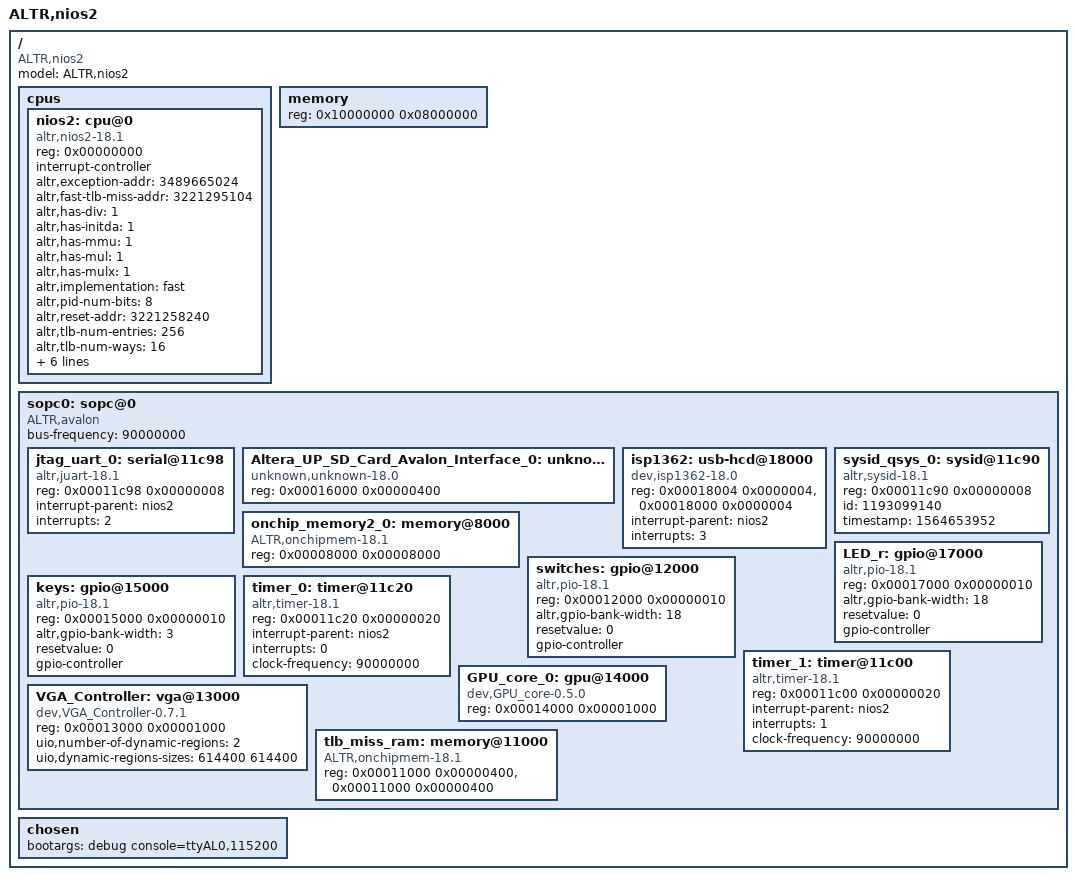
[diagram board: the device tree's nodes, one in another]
/*
 * This devicetree is generated by sopc2dts version unknown on Thu Aug 01 06:11:34 EDT 2019
 * Sopc2dts is written by Walter Goossens <waltergoossens@home.nl>
 * in cooperation with the nios2 community <nios2-dev@lists.rocketboards.org>
 */
/dts-v1/;

/ {
	model = "ALTR,nios2";
	compatible = "ALTR,nios2";
	#address-cells = <1>;
	#size-cells = <1>;

	cpus {
		#address-cells = <1>;
		#size-cells = <0>;

		nios2: cpu@0 {
			device_type = "cpu";
			compatible = "altr,nios2-18.1", "altr,nios2-1.1";
			reg = <0x00000000>;
			interrupt-controller;
			#interrupt-cells = <1>;
			altr,exception-addr = <3489665024>;	/* embeddedsw.dts.params.altr,exception-addr type NUMBER */
			altr,fast-tlb-miss-addr = <3221295104>;	/* embeddedsw.dts.params.altr,fast-tlb-miss-addr type NUMBER */
			altr,has-div = <1>;	/* embeddedsw.dts.params.altr,has-div type NUMBER */
			altr,has-initda = <1>;	/* embeddedsw.dts.params.altr,has-initda type NUMBER */
			altr,has-mmu = <1>;	/* embeddedsw.dts.params.altr,has-mmu type NUMBER */
			altr,has-mul = <1>;	/* embeddedsw.dts.params.altr,has-mul type NUMBER */
			altr,has-mulx = <1>;	/* embeddedsw.dts.params.altr,has-mulx type NUMBER */
			altr,implementation = "fast";	/* embeddedsw.dts.params.altr,implementation type STRING */
			altr,pid-num-bits = <8>;	/* embeddedsw.dts.params.altr,pid-num-bits type NUMBER */
			altr,reset-addr = <3221258240>;	/* embeddedsw.dts.params.altr,reset-addr type NUMBER */
			altr,tlb-num-entries = <256>;	/* embeddedsw.dts.params.altr,tlb-num-entries type NUMBER */
			altr,tlb-num-ways = <16>;	/* embeddedsw.dts.params.altr,tlb-num-ways type NUMBER */
			altr,tlb-ptr-sz = <8>;	/* embeddedsw.dts.params.altr,tlb-ptr-sz type NUMBER */
			clock-frequency = <90000000>;	/* embeddedsw.dts.params.clock-frequency type NUMBER */
			dcache-line-size = <32>;	/* embeddedsw.dts.params.dcache-line-size type NUMBER */
			dcache-size = <32768>;	/* embeddedsw.dts.params.dcache-size type NUMBER */
			icache-line-size = <32>;	/* embeddedsw.dts.params.icache-line-size type NUMBER */
			icache-size = <16384>;	/* embeddedsw.dts.params.icache-size type NUMBER */
		}; //end cpu@0 (nios2)
	}; //end cpus

	memory {
		device_type = "memory";
		reg = <0x10000000 0x08000000>;
	}; //end memory

	sopc0: sopc@0 {
		device_type = "soc";
		ranges;
		#address-cells = <1>;
		#size-cells = <1>;
		compatible = "ALTR,avalon", "simple-bus";
		bus-frequency = <90000000>;

		jtag_uart_0: serial@11c98 {
			compatible = "altr,juart-18.1", "altr,juart-1.0";
			reg = <0x00011c98 0x00000008>;
			interrupt-parent = <&nios2>;
			interrupts = <2>;
		}; //end serial@11c98 (jtag_uart_0)

		Altera_UP_SD_Card_Avalon_Interface_0: unknown@16000 {
			compatible = "unknown,unknown-18.0";
			reg = <0x00016000 0x00000400>;
		}; //end unknown@16000 (Altera_UP_SD_Card_Avalon_Interface_0)

		isp1362: usb-hcd@18000 {
			compatible = "dev,isp1362-18.0", "isp1362-hcd";
			reg = <0x00018004 0x0000004>,
                  <0x00018000 0x0000004>;
			interrupt-parent = <&nios2>;
			interrupts = <3>;
		}; //end unknown@18000 (isp1362)

		sysid_qsys_0: sysid@11c90 {
			compatible = "altr,sysid-18.1", "altr,sysid-1.0";
			reg = <0x00011c90 0x00000008>;
			id = <1193099140>;	/* embeddedsw.dts.params.id type NUMBER */
			timestamp = <1564653952>;	/* embeddedsw.dts.params.timestamp type NUMBER */
		}; //end sysid@11c90 (sysid_qsys_0)

		onchip_memory2_0: memory@8000 {
			device_type = "memory";
			compatible = "ALTR,onchipmem-18.1";
			reg = <0x00008000 0x00008000>;
		}; //end memory@8000 (onchip_memory2_0)

		LED_r: gpio@17000 {
			compatible = "altr,pio-18.1", "altr,pio-1.0";
			reg = <0x00017000 0x00000010>;
			altr,gpio-bank-width = <18>;	/* embeddedsw.dts.params.altr,gpio-bank-width type NUMBER */
			resetvalue = <0>;	/* embeddedsw.dts.params.resetvalue type NUMBER */
			#gpio-cells = <2>;
			gpio-controller;
		}; //end gpio@17000 (LED_r)

		switches: gpio@12000 {
			compatible = "altr,pio-18.1", "altr,pio-1.0";
			reg = <0x00012000 0x00000010>;
			altr,gpio-bank-width = <18>;	/* embeddedsw.dts.params.altr,gpio-bank-width type NUMBER */
			resetvalue = <0>;	/* embeddedsw.dts.params.resetvalue type NUMBER */
			#gpio-cells = <2>;
			gpio-controller;
		}; //end gpio@12000 (switches)

		keys: gpio@15000 {
			compatible = "altr,pio-18.1", "altr,pio-1.0";
			reg = <0x00015000 0x00000010>;
			altr,gpio-bank-width = <3>;	/* embeddedsw.dts.params.altr,gpio-bank-width type NUMBER */
			resetvalue = <0>;	/* embeddedsw.dts.params.resetvalue type NUMBER */
			#gpio-cells = <2>;
			gpio-controller;
		}; //end gpio@15000 (keys)

		timer_0: timer@11c20 {
			compatible = "altr,timer-18.1", "altr,timer-1.0";
			reg = <0x00011c20 0x00000020>;
			interrupt-parent = <&nios2>;
			interrupts = <0>;
			clock-frequency = <90000000>;	/* embeddedsw.dts.params.clock-frequency type NUMBER */
		}; //end timer@11c20 (timer_0)

		timer_1: timer@11c00 {
			compatible = "altr,timer-18.1", "altr,timer-1.0";
			reg = <0x00011c00 0x00000020>;
			interrupt-parent = <&nios2>;
			interrupts = <1>;
			clock-frequency = <90000000>;	/* embeddedsw.dts.params.clock-frequency type NUMBER */
		}; //end timer@11c00 (timer_1)

		VGA_Controller: vga@13000 {
			compatible = "dev,VGA_Controller-0.7.1", "dmem-uio";
			reg = <0x00013000 0x00001000>;
			uio,number-of-dynamic-regions = <2>;	/* embeddedsw.dts.params.uio,number-of-dynamic-regions type NUMBER */
            uio,dynamic-regions-sizes = <614400 614400>;
		}; //end vga@13000 (VGA_Controller)

		GPU_core_0: gpu@14000 {
			compatible = "dev,GPU_core-0.5.0", "dmem-uio";
			reg = <0x00014000 0x00001000>;
		}; //end gpu@14000 (GPU_core_0)

		tlb_miss_ram: memory@11000 {
			device_type = "memory";
			compatible = "ALTR,onchipmem-18.1";
			reg = <0x00011000 0x00000400>,
				<0x00011000 0x00000400>;
			reg-names = "s1", "s2";
		}; //end memory@11000 (tlb_miss_ram)
	}; //end sopc@0 (sopc0)

	chosen {
		bootargs = "debug console=ttyAL0,115200";
	}; //end chosen
}; //end /
